CM_ "IMPORT _community.dbc";
CM_ "IMPORT _honda_elesys_base.dbc";
CM_ "IMPORT _nidec_common.dbc";
CM_ "IMPORT _lkas_hud_4byte.dbc";
CM_ "IMPORT _nidec_scm_group_a_elesys.dbc";
CM_ "IMPORT _steering_sensors_c.dbc";
CM_ "IMPORT _steering_control_e.dbc";
CM_ "IMPORT _gearbox_legacy.dbc";
CM_ "IMPORT _sunnypilot_linbus_gw.dbc";

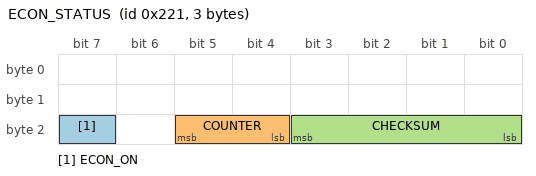
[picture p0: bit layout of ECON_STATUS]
BO_ 545 ECON_STATUS: 3 SCM
 SG_ ECON_ON : 23|1@0+ (1,0) [0|1] "" EON
 SG_ COUNTER : 21|2@0+ (1,0) [0|3] "" EON
 SG_ CHECKSUM : 19|4@0+ (1,0) [0|15] "" EON
